# CH583SFR register map
Vendor: WCH Ltd.; Series: CH58x; File version: 1.1
CPU: RISC-V r0p0, little endian, no MPU, no FPU, 2 interrupt priority bits
Registers are 8-bit, read-write, reset 0x0 unless marked. A register's access mark holds for its fields unless they carry their own. Offsets are from the block's base; [hi:lo] are bit positions; {n}, {i} and the like mark numbered series; 'fields as' and 'values as' point back to an identical list.

## USB2
Base 0x40008400
0x00 CTRL reset 0x6 — USB2 base control
  [7] UC_HOST_MODE — enable USB host mode: 0=device mode, 1=host mode
  [6] UC_LOW_SPEED — enable USB low speed: 0=12Mbps, 1=1.5Mbps
  [5] UC_DEV_PU_EN — USB device enable and internal pullup resistance enable
  [5:4] UC_SYS_CTRL — bit mask of USB system control
  [3] UC_INT_BUSY — enable automatic responding busy for device mode or automatic pause for host mode during interrupt flag UIF_TRANSFER valid
  [2] UC_RESET_SIE — force reset USB SIE, need software clear
  [1] UC_CLR_ALL — force clear FIFO and count of USB
  [0] UC_DMA_EN — DMA enable and DMA interrupt enable for USB
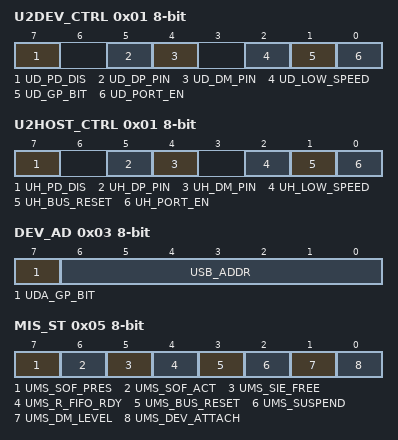
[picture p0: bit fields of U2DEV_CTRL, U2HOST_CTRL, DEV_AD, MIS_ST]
0x01 U2DEV_CTRL access per field — USB2 device physical prot control
  [7] UD_PD_DIS rw — disable USB UDP-UDM pulldown resistance: 0=enable pulldown, 1=disable
  [5] UD_DP_PIN ro — ReadOnly: indicate current UDP pin level
  [4] UD_DM_PIN ro — ReadOnly: indicate current UDM pin level
  [2] UD_LOW_SPEED rw — enable USB physical port low speed: 0=full speed, 1=low speed
  [1] UD_GP_BIT rw — general purpose bit
  [0] UD_PORT_EN rw — enable USB physical port I-O: 0=disable, 1=enable
0x01 U2HOST_CTRL access per field — USB2 device physical prot control
  [7] UH_PD_DIS ro — disable USB UDP-UDM pulldown resistance: 0=enable pulldown, 1=disable
  [5] UH_DP_PIN ro — ReadOnly: indicate current UDP pin level
  [4] UH_DM_PIN ro — ReadOnly: indicate current UDM pin level
  [2] UH_LOW_SPEED rw — enable USB port low speed: 0=full speed, 1=low speed
  [1] UH_BUS_RESET rw — control USB bus reset: 0=normal, 1=force bus reset
  [0] UH_PORT_EN rw — enable USB port: 0=disable, 1=enable port, automatic disabled if USB device detached
0x02 INT_EN — USB2 interrupt enable
  [6] UIE_DEV_NAK — enable interrupt for NAK responded for USB device mode
  [4] UIE_FIFO_OV — enable interrupt for FIFO overflow
  [3] UIE_HST_SOF — enable interrupt for host SOF timer action for USB host mode
  [2] UIE_SUSPEND — enable interrupt for USB suspend or resume event
  [1] UIE_TRANSFER — enable interrupt for USB transfer completion
  [0] UIE_BUS_RST — enable interrupt for USB bus reset event for USB device mode
  [0] UIE_DETECT — enable interrupt for USB device detected event for USB host mode
0x03 DEV_AD — USB2 device address
  [7] UDA_GP_BIT — general purpose bit
  [6:0] USB_ADDR — bit mask for USB device address
0x05 MIS_ST ro — USB2 miscellaneous status
  [7] UMS_SOF_PRES — RO, indicate host SOF timer presage status
  [6] UMS_SOF_ACT — RO, indicate host SOF timer action status for USB host
  [5] UMS_SIE_FREE — RO, indicate USB SIE free status
  [4] UMS_R_FIFO_RDY — RO, indicate USB receiving FIFO ready status (not empty)
  [3] UMS_BUS_RESET — RO, indicate USB bus reset status
  [2] UMS_SUSPEND — RO, indicate USB suspend status
  [1] UMS_DM_LEVEL — RO, indicate UDM level saved at device attached to USB host
  [0] UMS_DEV_ATTACH — RO, indicate device attached status on USB host
0x06 INT_FG reset 0x20 — USB2 interrupt flag
  [7] U_IS_NAK ro — RO, indicate current USB transfer is NAK received
  [6] U_TOG_OK ro — RO, indicate current USB transfer toggle is OK
  [5] U_SIE_FREE ro — RO, indicate USB SIE free status
  [4] UIF_FIFO_OV — RW,FIFO overflow interrupt flag for USB, direct bit address clear or write 1 to clear
  [3] UIF_HST_SOF — RW,host SOF timer interrupt flag for USB host, direct bit address clear or write 1 to clear
  [2] UIF_SUSPEND — RW,USB suspend or resume event interrupt flag, direct bit address clear or write 1 to clear
  [1] UIF_TRANSFER — RW,USB transfer completion interrupt flag, direct bit address clear or write 1 to clear
  [0] UIF_BUS_RST — RW,bus reset event interrupt flag for USB device mode, direct bit address clear or write 1 to clear
  [0] UIF_DETECT — RW,device detected event interrupt flag for USB host mode, direct bit address clear or write 1 to clear
0x07 INT_ST ro — USB2 interrupt status
  [7] UIS_SETUP_ACT — RO, indicate current USB transfer is NAK received for USB device mode
  [6] UIS_TOG_OK — RO, indicate current USB transfer toggle is OK
  [5:4] UIS_TOKEN — RO, bit mask of current token PID code received for USB device mode
    0=OUT; 2=IN; 3=SETUP
  [3:0] UIS_H_RES — RO, bit mask of current transfer handshake response for USB host mode: 0000=no response, time out from device, others=handshake response PID received
  [3:0] UIS_ENDP — RO, bit mask of current transfer endpoint number for USB device mode
0x08 RX_LEN ro — USB2 receiving length
  [7:0] USB_RX_LEN — RO,USB receiving length
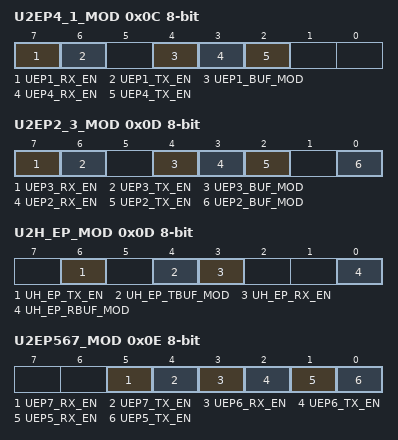
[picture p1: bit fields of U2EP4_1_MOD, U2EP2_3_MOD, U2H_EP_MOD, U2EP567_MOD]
0x0C U2EP4_1_MOD — endpoint 4/1 mode
  [7] UEP1_RX_EN — enable USB endpoint 1 receiving (OUT)
  [6] UEP1_TX_EN — enable USB endpoint 1 transmittal (IN)
  [4] UEP1_BUF_MOD — buffer mode of USB endpoint 1
  [3] UEP4_RX_EN — enable USB endpoint 4 receiving (OUT)
  [2] UEP4_TX_EN — enable USB endpoint 4 transmittal (IN)
0x0D U2EP2_3_MOD — endpoint 2_3 mode
  [7] UEP3_RX_EN — enable USB endpoint 3 receiving (OUT)
  [6] UEP3_TX_EN — enable USB endpoint 3 transmittal (IN)
  [4] UEP3_BUF_MOD — buffer mode of USB endpoint 3
  [3] UEP2_RX_EN — enable USB endpoint 2 receiving (OUT)
  [2] UEP2_TX_EN — enable USB endpoint 2 transmittal (IN)
  [0] UEP2_BUF_MOD — buffer mode of USB endpoint 2
0x0D U2H_EP_MOD — host endpoint mode
  [6] UH_EP_TX_EN — enable USB host OUT endpoint transmittal
  [4] UH_EP_TBUF_MOD — buffer mode of USB host OUT endpoint
  [3] UH_EP_RX_EN — enable USB host IN endpoint receiving
  [0] UH_EP_RBUF_MOD — buffer mode of USB host IN endpoint
0x0E U2EP567_MOD — USB2 endpoint 5/6/7 mode
  [5] UEP7_RX_EN — enable USB endpoint 7 receiving (OUT)
  [4] UEP7_TX_EN — enable USB endpoint 7 transmittal (IN)
  [3] UEP6_RX_EN — enable USB endpoint 6 receiving (OUT)
  [2] UEP6_TX_EN — enable USB endpoint 6 transmittal (IN)
  [1] UEP5_RX_EN — enable USB endpoint 5 receiving (OUT)
  [0] UEP5_TX_EN — enable USB endpoint 5 transmittal (IN)
0x10 U2EP0_DMA 16-bit — endpoint 0 DMA buffer address
  [15:0] UEP0_DMA — RW,endpoint 0 DMA buffer address
{0x10+4i} U2EP{i}_DMA 16-bit (i=1..3) — USB2 endpoint {i} DMA buffer address
  [15:0] UEP{i}_DMA — RW,endpoint {i} DMA buffer address
0x18 U2H_RX_DMA 16-bit — host rx endpoint buffer high address
  [15:0] UH_RX_DMA — RW,host rx endpoint buffer high address
0x1C U2H_TX_DMA 16-bit — host tx endpoint buffer high address
  [15:0] UH_TX_DMA — RW,host tx endpoint buffer high address
{0x20+4i} U2EP{i}_T_LEN (i=0..4) — USB2 endpoint {i} transmittal length
  [7:0] UEP{i}_T_LEN — endpoint {i} transmittal length
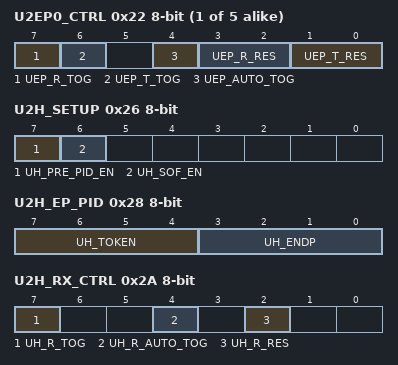
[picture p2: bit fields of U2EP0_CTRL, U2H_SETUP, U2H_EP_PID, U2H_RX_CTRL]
{0x22+4i} U2EP{i}_CTRL (i=0..4) — USB2 endpoint {i} control
  [7] UEP_R_TOG — expected data toggle flag of USB endpoint X receiving (OUT): 0=DATA0, 1=DATA1
  [6] UEP_T_TOG — prepared data toggle flag of USB endpoint X transmittal (IN): 0=DATA0, 1=DATA1
  [4] UEP_AUTO_TOG — enable automatic toggle after successful transfer completion on endpoint 1_2_3: 0=manual toggle, 1=automatic toggle
  [3:2] UEP_R_RES — bit mask of handshake response type for USB endpoint X receiving (OUT)
    0=ACK; 2=NAK; 3=STALL
  [1:0] UEP_T_RES — bit mask of handshake response type for USB endpoint X transmittal (IN)
    0=ACK; 2=NAK; 3=STALL
0x26 U2H_SETUP — host aux setup
  [7] UH_PRE_PID_EN — USB host PRE PID enable for low speed device via hub
  [6] UH_SOF_EN — USB host automatic SOF enable
0x28 U2H_EP_PID — host endpoint and PID
  [7:4] UH_TOKEN — bit mask of token PID for USB host transfer
  [3:0] UH_ENDP — bit mask of endpoint number for USB host transfer
0x2A U2H_RX_CTRL — host receiver endpoint control
  [7] UH_R_TOG — expected data toggle flag of host receiving (IN): 0=DATA0, 1=DATA1
  [4] UH_R_AUTO_TOG — enable automatic toggle after successful transfer completion: 0=manual toggle, 1=automatic toggle
  [2] UH_R_RES — bit mask of handshake response type for USB endpoint X receiving (OUT)
0x2C U2H_TX_LEN — host transmittal endpoint transmittal length
  [7:0] UH_TX_LEN
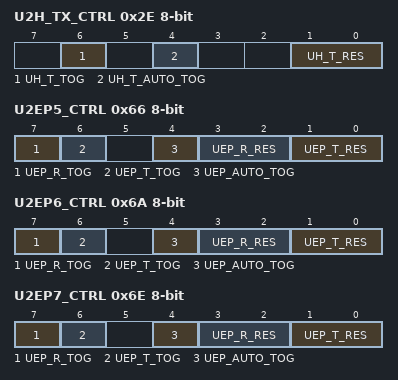
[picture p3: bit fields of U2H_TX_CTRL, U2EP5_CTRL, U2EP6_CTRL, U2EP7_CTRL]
0x2E U2H_TX_CTRL — host transmittal endpoint control
  [6] UH_T_TOG — prepared data toggle flag of USB endpoint X transmittal (IN): 0=DATA0, 1=DATA1
  [4] UH_T_AUTO_TOG — enable automatic toggle after successful transfer completion on endpoint 1_2_3: 0=manual toggle, 1=automatic toggle
  [1:0] UH_T_RES — bit mask of handshake response type for USB endpoint X transmittal (IN)
{0x40+4i} U2EP{i}_DMA 16-bit (i=5..7) — USB2 endpoint {i} DMA buffer address
  [15:0] UEP{i}_DMA — RW,endpoint {i} DMA buffer address
{0x50+4i} U2EP{i}_T_LEN (i=5..7) — USB2 endpoint {i} transmittal length
  [7:0] UEP{i}_T_LEN — endpoint {i} transmittal length
0x66 U2EP5_CTRL — USB2 endpoint 5 control
  fields as U2EP0_CTRL
0x6A U2EP6_CTRL — USB2 endpoint 6 control
  fields as U2EP0_CTRL
0x6E U2EP7_CTRL — USB2 endpoint 7 control
  [7] UEP_R_TOG — expected data toggle flag of USB endpoint X receiving (OUT): 0=DATA0, 1=DATA1
  [6] UEP_T_TOG — prepared data toggle flag of USB endpoint X transmittal (IN): 0=DATA0, 1=DATA1
  [4] UEP_AUTO_TOG — enable automatic toggle after successful transfer completion on endpoint 1_2_3: 0=manual toggle, 1=automatic toggle
  [3:2] UEP_R_RES — bit mask of handshake response type for USB endpoint X receiving (OUT)
  [1:0] UEP_T_RES — bit mask of handshake response type for USB endpoint X transmittal (IN)
